# RX64M_EPTPC_Pilot register map
File version: 1.0
RX64M_EPTPC_Pilot peripheral registers generated from iodefine.h (pilot).
Registers are 32-bit, read-write, reset 0x0 unless marked. A register's access mark holds for its fields unless they carry their own. Offsets are from the block's base; lines under a group give offsets from that group; [hi:lo] are bit positions; {n}, {i} and the like mark numbered series; 'fields as' and 'values as' point back to an identical list; <NAME> marks a mode.

## Memory map
0x000C0500 EPTPC size 0x3F38
0x000C4800 EPTPC0 size 0x1D8
0x000C4C00 EPTPC1 size 0x1D8

## EPTPC
Base 0x000C0500
0x00 PTRSTR
  [0] RESET
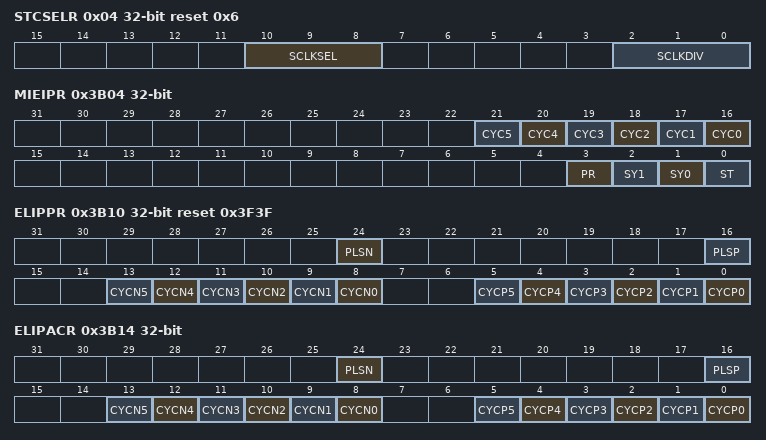
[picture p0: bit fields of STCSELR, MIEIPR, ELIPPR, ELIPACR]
0x04 STCSELR reset 0x6
  [10:8] SCLKSEL, [2:0] SCLKDIV
0x3B00 MIESR
0x3B04 MIEIPR
  [n+16] CYC{n} (n=0..5), [3] PR, [2] SY1, [1] SY0, [0] ST
0x3B10 ELIPPR reset 0x3F3F
  [24] PLSN, [16] PLSP, [n+8] CYCN{n} (n=0..5), [n] CYCP{n} (n=0..5)
0x3B14 ELIPACR
  [24] PLSN, [16] PLSP, [n+8] CYCN{n} (n=0..5), [n] CYCP{n} (n=0..5)
0x3B40 STSR
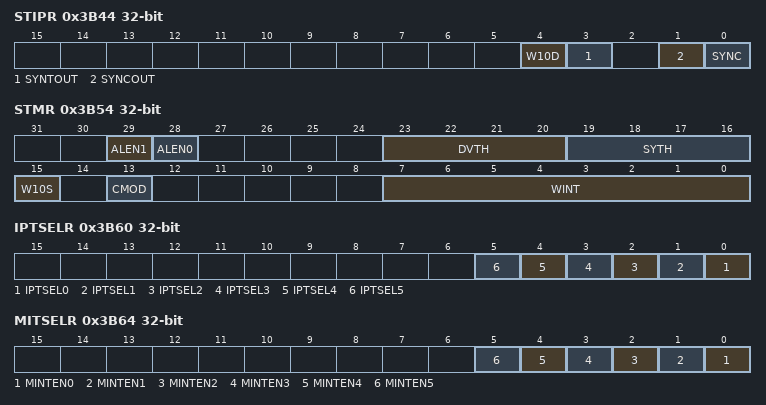
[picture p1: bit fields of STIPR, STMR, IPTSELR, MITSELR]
0x3B44 STIPR
  [4] W10D, [3] SYNTOUT, [1] SYNCOUT, [0] SYNC
0x3B50 STCFR
  [1:0] STCF
0x3B54 STMR
  [29] ALEN1, [28] ALEN0, [23:20] DVTH, [19:16] SYTH, [15] W10S, [13] CMOD, [7:0] WINT
0x3B58 SYNTOR
0x3B60 IPTSELR
  [n] IPTSEL{n} (n=0..5)
0x3B64 MITSELR
  [n] MINTEN{n} (n=0..5)
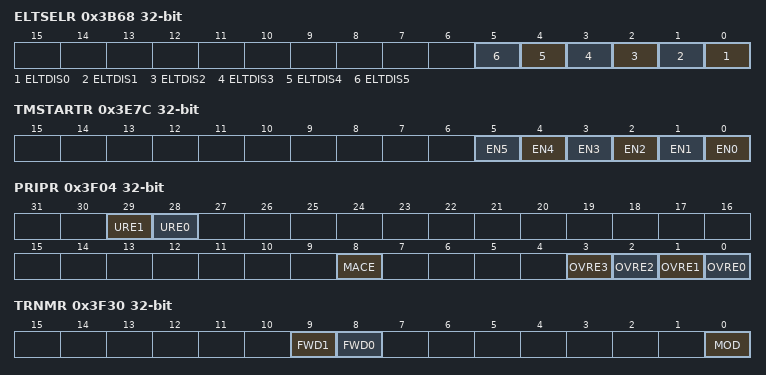
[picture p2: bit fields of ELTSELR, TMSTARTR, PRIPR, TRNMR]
0x3B68 ELTSELR
  [n] ELTDIS{n} (n=0..5)
0x3B6C STCHSELR
  [0] SYSEL
0x3B80 SYNSTARTR
  [0] STR
0x3B84 LCIVLDR
  [0] LOAD
0x3B90 SYNTDARU
0x3B94 SYNTDARL
0x3B98 SYNTDBRU
0x3B9C SYNTDBRL
0x3BB0 LCIVRU
  [15:0] VALU
0x3BB4 LCIVRM
0x3BB8 LCIVRL
0x3C24 GETW10R
  [0] GW10
0x3C28 PLIMITRU
  [30:0] LMTU
0x3C2C PLIMITRM
0x3C30 PLIMITRL
0x3C34 MLIMITRU
  [30:0] LMTU
0x3C38 MLIMITRM
0x3C3C MLIMITRL
0x3C40 GETINFOR
  [0] INFO
0x3C70 LCCVRU ro
  [15:0] CNTU
0x3C74 LCCVRM ro
0x3C78 LCCVRL ro
0x3D10 PW10VRU ro
0x3D14 PW10VRM ro
0x3D18 PW10VRL ro
0x3DD0 MW10RU ro
0x3DD4 MW10RM ro
0x3DD8 MW10RL ro
{0x3E00+0x10*i} TMSTTRU{i} (i=0..5)
{0x3E04+0x10*i} TMSTTRL{i} (i=0..5)
{0x3E08+0x10*i} TMCYCR{i} (i=0..5)
  [29:0] CYC
{0x3E0C+0x10*i} TMPLSR{i} (i=0..5)
  [28:0] WTH
0x3E7C TMSTARTR
  [n] EN{n} (n=0..5)
0x3F00 PRSR (reset mask 0xF000FFFF)
0x3F04 PRIPR
  [29] URE1, [28] URE0, [8] MACE, [n] OVRE{n} (n=0..3)
0x3F10 PRMACRU0
  [23:0] MACU
0x3F14 PRMACRL0
  [23:0] MACL
0x3F18 PRMACRU1
  [23:0] MACU
0x3F1C PRMACRL1
  [23:0] MACL
0x3F20 TRNDISR
  [1:0] TDIS
0x3F30 TRNMR
  [9] FWD1, [8] FWD0, [0] MOD
0x3F34 TRNCTTDR reset 0x60
  [10:0] THVAL

## EPTPC0
Base 0x000C4800
Same registers: EPTPC1 0x000C4C00
0x00 SYSR (reset mask 0xFF03FFFF)
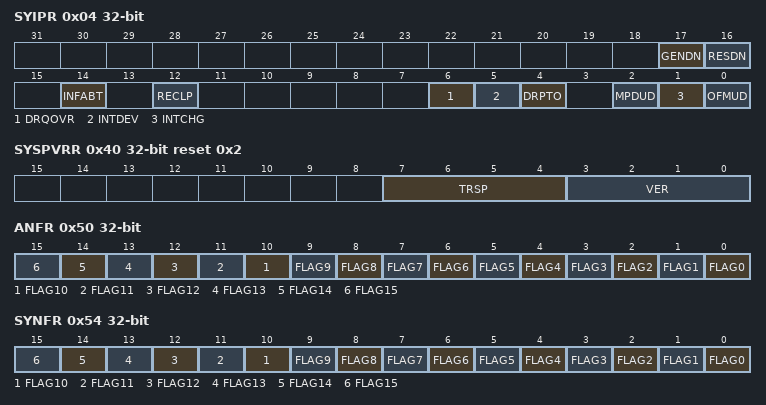
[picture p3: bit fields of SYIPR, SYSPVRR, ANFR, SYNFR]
0x04 SYIPR
  [17] GENDN, [16] RESDN, [14] INFABT, [12] RECLP, [6] DRQOVR, [5] INTDEV, [4] DRPTO, [2] MPDUD, [1] INTCHG, [0] OFMUD
0x10 SYMACRU
  [23:0] MACU
0x14 SYMACRL
  [23:0] MACL
0x1C SYIPADDRR
0x40 SYSPVRR reset 0x2
  [7:4] TRSP, [3:0] VER
0x44 SYDOMR
  [7:0] DNUM
0x50 ANFR
  [n] FLAG{n} (n=0..15)
0x54 SYNFR
  [n] FLAG{n} (n=0..15)
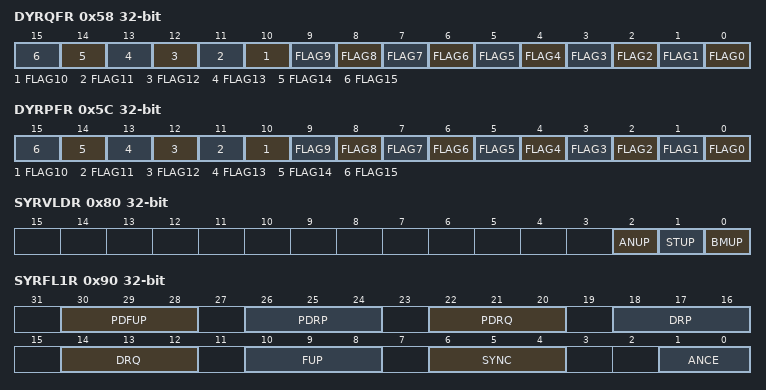
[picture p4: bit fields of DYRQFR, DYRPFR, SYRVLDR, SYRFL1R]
0x58 DYRQFR
  [n] FLAG{n} (n=0..15)
0x5C DYRPFR
  [n] FLAG{n} (n=0..15)
0x60 SYCIDRU
0x64 SYCIDRL
0x68 SYPNUMR
  [15:0] PNUM
0x80 SYRVLDR
  [2] ANUP, [1] STUP, [0] BMUP
0x90 SYRFL1R
  [30:28] PDFUP, [26:24] PDRP, [22:20] PDRQ, [18:16] DRP, [14:12] DRQ, [10:8] FUP, [6:4] SYNC, [1:0] ANCE
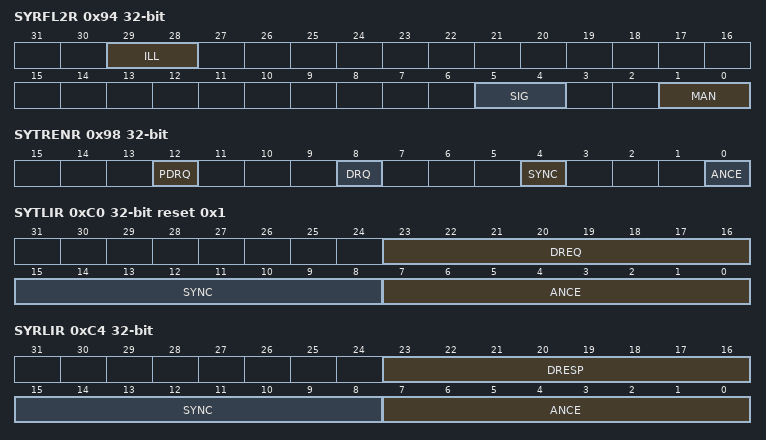
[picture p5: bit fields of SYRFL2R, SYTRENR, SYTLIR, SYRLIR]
0x94 SYRFL2R
  [29:28] ILL, [5:4] SIG, [1:0] MAN
0x98 SYTRENR
  [12] PDRQ, [8] DRQ, [4] SYNC, [0] ANCE
0xA0 MTCIDU
0xA4 MTCIDL
0xA8 MTPID
  [15:0] PNUM
0xC0 SYTLIR reset 0x1
  [23:16] DREQ, [15:8] SYNC, [7:0] ANCE
0xC4 SYRLIR ro
  [23:16] DRESP, [15:8] SYNC, [7:0] ANCE
0xC8 OFMRU ro
0xCC OFMRL ro
0xD0 MPDRU ro
0xD4 MPDRL ro
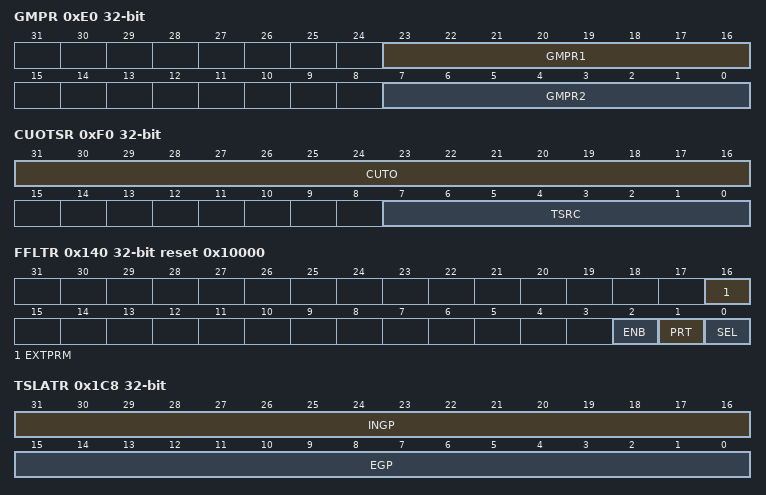
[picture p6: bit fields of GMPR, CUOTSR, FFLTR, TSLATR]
0xE0 GMPR
  [23:16] GMPR1, [7:0] GMPR2
0xE4 GMCQR
0xE8 GMIDRU
0xEC GMIDRL
0xF0 CUOTSR
  [31:16] CUTO, [7:0] TSRC
0xF4 SRR
  [15:0] SRMV
0x100 PPMACRU reset 0x11B19
  [23:0] MACU
0x104 PPMACRL
  [23:0] MACL
0x108 PDMACRU reset 0x180C2
  [23:0] MACU
0x10C PDMACRL reset 0xE
  [23:0] MACL
0x110 PETYPER reset 0x88F7
  [15:0] TYPE
0x120 PPIPR reset 0xE0000181
0x124 PDIPR reset 0xE000006B
0x128 PETOSR
  [7:0] EVTO
0x12C PGTOSR
  [7:0] GETO
0x130 PPTTLR reset 0x80
  [7:0] PRTL
0x134 PDTTLR reset 0x1
  [7:0] PDTL
0x138 PEUDPR reset 0x13F
  [15:0] EVUPT
0x13C PGUDPR reset 0x140
  [15:0] GEUPT
0x140 FFLTR reset 0x10000
  [16] EXTPRM, [2] ENB, [1] PRT, [0] SEL
0x160 FMAC0RU
  [23:0] MACU
0x164 FMAC0RL
  [23:0] MACL
0x168 FMAC1RU
  [23:0] MACU
0x16C FMAC1RL
  [23:0] MACL
0x1C0 DASYMRU
  [15:0] ASYMU
0x1C4 DASYMRL
0x1C8 TSLATR
  [31:16] INGP, [15:0] EGP
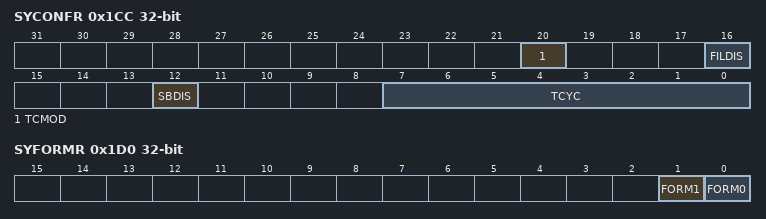
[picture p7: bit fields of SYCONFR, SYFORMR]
0x1CC SYCONFR
  [20] TCMOD, [16] FILDIS, [12] SBDIS, [7:0] TCYC
0x1D0 SYFORMR
  [1] FORM1, [0] FORM0
0x1D4 RSTOUTR
